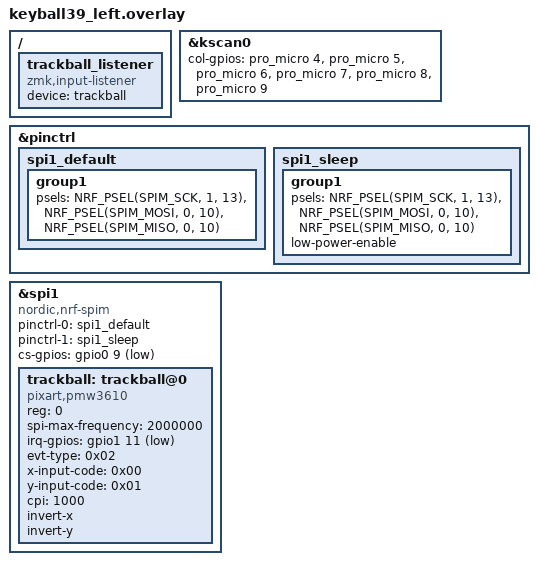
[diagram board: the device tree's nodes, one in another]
/*
 * Copyright (c) 2020 ZMK Contributors
 *
 * SPDX-License-Identifier: MIT
 */

#include "keyball39.dtsi"

&kscan0 {
	col-gpios
		= <&pro_micro 4 GPIO_ACTIVE_HIGH>
		, <&pro_micro 5 GPIO_ACTIVE_HIGH>
		, <&pro_micro 6 GPIO_ACTIVE_HIGH>
		, <&pro_micro 7 GPIO_ACTIVE_HIGH>
		, <&pro_micro 8 GPIO_ACTIVE_HIGH>
		, <&pro_micro 9 GPIO_ACTIVE_HIGH>
		;
};

&pinctrl {
    spi1_default: spi1_default {
        group1 {
            psels = <NRF_PSEL(SPIM_SCK, 1, 13)>,
                <NRF_PSEL(SPIM_MOSI, 0, 10)>,
                <NRF_PSEL(SPIM_MISO, 0, 10)>;
        };
    };

    spi1_sleep: spi1_sleep {
        group1 {
            psels = <NRF_PSEL(SPIM_SCK, 1, 13)>,
                <NRF_PSEL(SPIM_MOSI, 0, 10)>,
                <NRF_PSEL(SPIM_MISO, 0, 10)>;
            low-power-enable;
        };
    };
};

&spi1 {
    status = "okay";
    compatible = "nordic,nrf-spim";
    pinctrl-0 = <&spi1_default>;
    pinctrl-1 = <&spi1_sleep>;
    pinctrl-names = "default", "sleep";
    cs-gpios = <&gpio0 9 GPIO_ACTIVE_LOW>;

    trackball: trackball@0 {
        status = "okay";
        compatible = "pixart,pmw3610";
        reg = <0>;
        spi-max-frequency = <2000000>;
        irq-gpios = <&gpio1 11 (GPIO_ACTIVE_LOW | GPIO_PULL_UP)>;
        evt-type = <0x02>;  // EV_REL - relative movement events
        x-input-code = <0x00>;  // REL_X
        y-input-code = <0x01>;  // REL_Y
        cpi = <1000>;
        invert-x;
        invert-y;
        // TODO: Re-enable automouse layer once we figure out correct property
        // automouse-layer = <4>;
    };
};

/ {
  trackball_listener {
    compatible = "zmk,input-listener";
    device = <&trackball>;

    // TODO: Re-enable scroll and snipe modes once input processors are properly configured
    // Scroll mode - convert XY movement to scroll on layer 5
    // scroll_mode {
    //   layers = <5>;
    //   input-processors = <&zip_xy_to_scroll_mapper>;
    // };

    // Snipe mode - slow down movement for precision on layer 6
    // snipe_mode {
    //   layers = <6>;
    //   input-processors = <&zip_xy_scaler 1 4>;
    // };
  };
};
